# PCIE1_CORE_DBN_CFG_PCIE_CORE register map
Vendor: Texas Instruments
Registers are 32-bit, read-write, reset 0x0 unless marked. A register's access mark holds for its fields unless they carry their own. Offsets are as the file gives them; [hi:lo] are bit positions.

## PCIE1_CORE_DBN_CFG_PCIE_CORE (part 2 of 7)
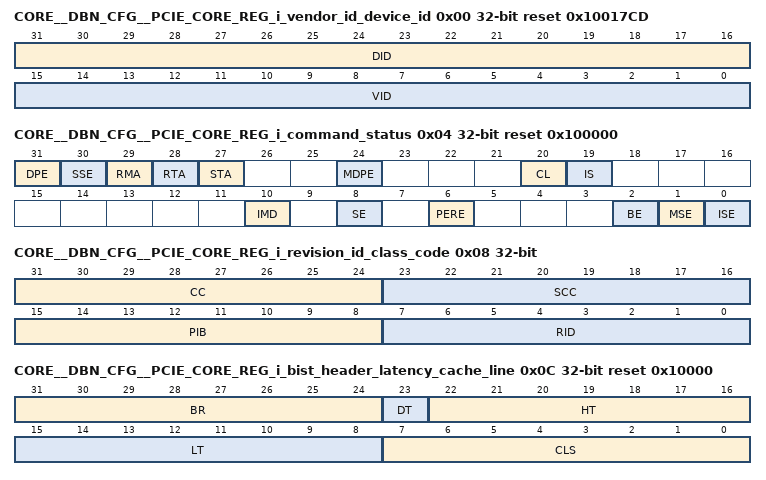
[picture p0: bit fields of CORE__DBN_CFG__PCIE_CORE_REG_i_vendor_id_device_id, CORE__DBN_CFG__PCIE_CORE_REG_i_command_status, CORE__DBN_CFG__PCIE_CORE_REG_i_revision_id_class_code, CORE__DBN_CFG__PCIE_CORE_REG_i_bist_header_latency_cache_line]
0x00 CORE__DBN_CFG__PCIE_CORE_REG_i_vendor_id_device_id ro reset 0x10017CD — 16-bit Vendor ID register and 16-bit Device ID register.
  [31:16] DID — Device ID assigned by the manufacturer of the device. On power-up, the Controller sets it to the value defined in the RTL file reg_defaults.h. This field can be written from the APB bus by setting [21] bit high of the pcie_mgmt_APB_ADDR during a local management register write.
  [15:0] VID — This is the Vendor ID assigned by PCI SIG to the manufacturer of the device. The Vendor ID is set in the Vendor ID Register within the local management register block.
0x04 CORE__DBN_CFG__PCIE_CORE_REG_i_command_status access not given reset 0x100000 — 16-bit Command Register and 16-bit Status Register.
  [31] DPE — This bit is set when the Controller has received a poisoned TLP. The Parity Error Response enable bit [bit 6] has no effect on the setting of this bit. This field can also be cleared from the local management bus APB by writing a 1 into this bit position. This field can be forced to 1 from the APB bus by setting [21] bit high of the pcie_mgmt_APB_ADDR during a local management register write. (access R/W1TC)
  [30] SSE — The Controller sets this bit [i]On receiving an error message from the link, if SERR-Enable in PCI Command Register is 1 and SERR-Enable in the Bridge Control Register is also 1. [ii]On any internal Fatal/Non-Fatal error detected, if SERR-Enable in PCI Command Register is 1. This field can also be cleared from the local management APB bus by writing a 1 into this bit position. This field can be forced to 1 from the APB bus by setting [21] bit high of the pcie_mgmt_APB_ADDR during a local management register write. (access R/W1TC)
  [29] RMA — This bit is set when the Controller has received a completion from the link with the Unsupported Request status. This field can also be cleared from the local management APB bus by writing a 1 into this bit position This field can be forced to 1 from the APB bus by setting [21] bit high of the pcie_mgmt_APB_ADDR during a local management register write. (access R/W1TC)
  [28] RTA — This bit is set when the Controller has received a completion from the link with the Completer Abort status. This field can also be cleared from the local management APB bus by writing a 1 into this bit position. This field can be written from the APB bus by setting [21] bit high of the pcie_mgmt_APB_ADDR during a local management register write. (access R/W1TC)
  [27] STA — This bit is set when the Controller has sent a completion to the link with the Completer Abort status. This field can also be cleared from the local management APB bus by writing a 1 into this bit position. This field can be forced to 1 from the APB bus by setting [21] bit high of the pcie_mgmt_APB_ADDR during a local management register write. (access R/W1TC)
  [24] MDPE — When the Parity Error Response enable bit is 1, the Controller sets this bit when it detects the following error conditions: [i] The Controller receives a poisoned request from the link. [ii] The Controller has sent a Poisoned Completion downstream to the link This bit remains 0 when the Parity Error Response enable bit is 0. This field can be forced to 1 from the APB bus by setting [21] bit high of the pcie_mgmt_APB_ADDR during a local management register write. (access R/W1TC)
  [20] CL ro — Indicates the presence of PCI Extended Capabilities registers. This bit is hardwired to 1.
  [19] IS ro — This bit is valid only when the Controller is configured to support legacy interrupts. Indicates that the Controller has a pending interrupt, that is, the Controller has sent an Assert_INTx message but has not transmitted a corresponding Deassert_INTx message.
  [10] IMD rw — Enables or disables the transmission of INTx Assert and De-assert messages from the Controller. The setting of this bit has no effect on the operation of the Controller in the RC mode.
  [8] SE rw — Enables the reporting of fatal and non-fatal errors detected by the Controller to the Root Complex.
  [6] PERE rw — When this bit is 1, the Controller sets the Master Data Parity Error status bit when it detects the following error conditions: [i] The Controller receives a poisoned completion from the link in response to a request. [ii] The Controller sends out a poisoned write request on the link [this may be because an underflow occurred during the packet transfer at the host interface of the Controller.]. When this bit is 0, the Master Data Parity Error status bit is never set.
  [2] BE rw — For a Function with a Type 1 Configurations Space header[Controller in RP Mode], this bit controls forwarding of Memory or I/O Requests by a Port in the Upstream direction. Note: The Controller does not generate any response based on this bit. Client application logic must use this bit and respond to requests appropriately: - When this bit is '1', Client logic can process the Memory and IO Requests received from PCIe Link normally. - When this bit is '0', Client logic must handle Memory and IO Requests received from PCIe Link as Unsupported Requests.
  [1] MSE rw — For a Function with a Type 1 Configuration Space header[Controller in RP Mode], this bit controls the response to Memory Space accesses received on its Primary Side. Note: The Controller does not generate any response based on this bit. - Client must check for this bit to be '1' before initiating any Memory requests on the pcie_master_AXI interface.
  [0] ISE rw — For a Function with a Type 1 Configuration Space header [Controller in RP Mode] , this bit controls the response to I/O Space accesses received on its Primary Side. Note: The Controller does not generate any response based on this bit. - Client must check for this bit to be '1' before initiating any IO requests on the pcie_master_AXI interface.
0x08 CORE__DBN_CFG__PCIE_CORE_REG_i_revision_id_class_code ro — This register contains the Revision ID and Class Code associated with the device incorporating the Cadence PCIe Controller.
  [31:24] CC — Identifies the function of the device. On power-up, the Controller sets it to the value defined in the RTL file reg_defaults.h. This field can be written from the APB bus by setting [21] bit high of the pcie_mgmt_APB_ADDR during a local management register write.
  [23:16] SCC — Identifies a sub-category within the selected function. This field can be written from the APB bus by setting [21] bit high of the pcie_mgmt_APB_ADDR during a local management register write.
  [15:8] PIB — Identifies the register set layout of the device. This field can be written from the APB bus by setting [21] bit high of the pcie_mgmt_APB_ADDR during a local management register write.
  [7:0] RID — Assigned by the manufacturer of the device to identify the revision number of the device. This field can be written from the APB bus by setting [21] bit high of the pcie_mgmt_APB_ADDR during a local management register write.
0x0C CORE__DBN_CFG__PCIE_CORE_REG_i_bist_header_latency_cache_line access per field reset 0x10000 — This location contains the BIST, header-type, Latency Timer and Cache Line Size Registers.
  [31:24] BR ro — BIST control register. This field can be written from the APB bus by setting [21] bit high of the pcie_mgmt_APB_ADDR during a local management register write.
  [23] DT ro — Identifies whether the device supports a single Function or multiple Functions. Hardwired to zero
  [22:16] HT ro — Identifies format of header. This field is hardwired to 1.
  [15:8] LT ro — This is an unused field and is hardwired to 0.
  [7:0] CLS rw — Cache Line Size Register defined in PCI Specifications 3.0. This field can be read or written, both from the link and from the local management bus, but its value is not used.
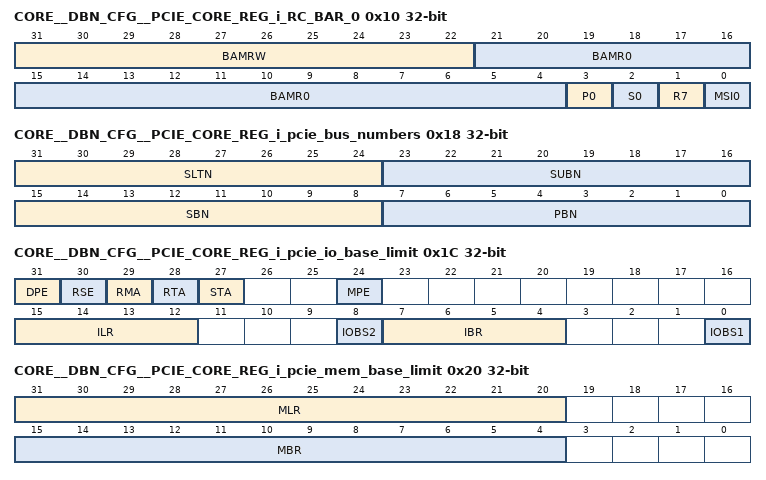
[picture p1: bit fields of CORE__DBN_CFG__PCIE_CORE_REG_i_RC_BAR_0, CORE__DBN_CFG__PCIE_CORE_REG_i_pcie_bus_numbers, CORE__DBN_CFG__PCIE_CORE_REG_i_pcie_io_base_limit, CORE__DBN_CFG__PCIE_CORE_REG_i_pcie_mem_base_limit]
0x10 CORE__DBN_CFG__PCIE_CORE_REG_i_RC_BAR_0 access per field — This is the Base Address Register 0 in the Type-1 Config Space. It can be configured as a 32-bit memory BAR, a 32-bit IO BAR, or can be paired with RC BAR 1 to form a 64-bit memory BAR. The parameters of this BAR are configured in the local management register Root Complex BAR Configuration Register.
  [31:22] BAMRW rw — This field defines the base address of the memory address range. The number of implemented bits in this field determines the BAR aperture configured in Root Complex BAR Configuration Register. All other bits are not writeable, and are read as 0's.
  [21:4] BAMR0 ro — This field defines the base address of the memory address range. The number of implemented bits in this field determines the BAR aperture configured in Root Complex BAR Configuration Register. All other bits are not writeable, and are read as 0's.
  [3] P0 ro — For memory BAR: This bit reads as 1 when BAR 0 is configured as a prefetchable BAR, and as 0 when configured as a non-prefetchable BAR. For IO BAR: This is bit 3 of the base address. The value read in this field is determined by the setting of Root Complex BAR Configuration Register.
  [2] S0 ro — For memory BAR:This bit reads as 0 when BAR 0 is configured as a 32-bit BAR, and as 1 when configured as a 64-bit BAR. For IO BAR: This is bit 3 of the base address. The value read in this field is determined by the setting of Root Complex BAR Configuration Register.
  [1] R7 ro — This bit is hardwired to 0 for both memory and I/O BARs.
  [0] MSI0 ro — Specifies whether this BAR defines a memory address range or an I/O address range [0 = memory, 1 = I/O]. The value read in this field is determined by the setting of Root Complex BAR Configuration Register.
0x14 CORE__DBN_CFG__PCIE_CORE_REG_i_RC_BAR_1 ro — This is the Base Address Register 1 in the Type-1 Config Space. It can be configured as a 32-bit memory BAR, a 32-bit IO BAR, or can be paired with RC BAR 0 to form a 64-bit memory BAR. The parameters of this BAR are configured in the local management register Root Complex BAR Configuration Register.
  [31:0] R7 — This field is reserved at power-on. This can be changed using BAR configuration regsiter in LM space.
0x18 CORE__DBN_CFG__PCIE_CORE_REG_i_pcie_bus_numbers access per field — This location contains the 8-bit fields: Primary Bus Number, Secondary Bus Number,Subordinate Bus Number, Secondary Latency Timer.
  [31:24] SLTN ro — This field is not implemented.
  [23:16] SUBN rw — This field can be read and written from the local management bus, but its value is not used within the Controller.
  [15:8] SBN rw — This field can be read and written from the local management bus, but its value is not used within the Controller.
  [7:0] PBN rw — This field can be read and written from the local management bus, but its value is not used within the Controller.
0x1C CORE__DBN_CFG__PCIE_CORE_REG_i_pcie_io_base_limit access not given — This location contains the 8-bit IO Base Register, the 8-bit IO Limit Register and the 16-bit Secondary Status Registers.
  [31] DPE — The Controller does not set this bit by itself. This bit can be cleared by writing a 1 into this bit position from the local management APB bus. This field can be forced to 1 or 0 from the APB bus by setting [21] bit high of the pcie_mgmt_APB_ADDR during a local management register write. (access R/W1TC)
  [30] RSE — The Controller does not set this bit by itself. This bit can be cleared by writing a 1 into this bit position from the local management APB bus. This field can be forced to 1 or 0 from the APB bus by setting [21] bit high of the pcie_mgmt_APB_ADDR during a local management register write. (access R/W1TC)
  [29] RMA — The Controller does not set this bit by itself. This bit can be cleared by writing a 1 into this bit position from the local management APB bus. This field can be forced to 1 or 0 from the APB bus by setting [21] bit high of the pcie_mgmt_APB_ADDR during a local management register write. (access R/W1TC)
  [28] RTA — The Controller does not set this bit by itself. This bit can be cleared by writing a 1 into this bit position from the local management APB bus. This field can be forced to 1 or 0 from the APB bus by setting [21] bit high of the pcie_mgmt_APB_ADDR during a local management register write. (access R/W1TC)
  [27] STA — The Controller does not set this bit by itself. This bit can be cleared by writing a 1 into this bit position from the local management APB bus. This field can be forced to 1 or 0 from the APB bus by setting [21] bit high of the pcie_mgmt_APB_ADDR during a local management register write. (access R/W1TC)
  [24] MPE — The Controller does not set this bit by itself. This bit can be cleared by writing a 1 into this bit position from the local management APB bus. This field can be forced to 1 or 0 from the APB bus by setting [21] bit high of the pcie_mgmt_APB_ADDR during a local management register write. Note that this bit can be set only when the Parity Error Response Enable bit is set in the Bridge Control Register (access R/W1TC)
  [15:12] ILR ro — This field can be read and written from the local management bus if IO BAR is enabled in the Root Complex BAR configuration register, else it is hardwired to zero. Its value is not used within the Controller.
  [8] IOBS2 ro — value set in Type1 cfg IO bar size[bit 20 of RC BAR CONFIG register].If type1 cfg IObar enable bit[bit 19 in RC BAR CONFIG register] is not set, then this field will be hard coded to 0.
  [7:4] IBR ro — This field can be read and written from the local management bus if IO BAR is enabled in the Root Complex BAR configuration register, else it is hardwired to zero. Its value is not used within the Controller.
  [0] IOBS1 ro — value set in Type1 cfg IO bar size[bit 20 of RC BAR CONFIG register]. If type1 cfg IObar enable bit[bit 19 in RC BAR CONFIG register] is not set, then this field will be hard coded to 0.
0x20 CORE__DBN_CFG__PCIE_CORE_REG_i_pcie_mem_base_limit — This location contains the 16-bit Memory Base Register and the 16-bit Memory Limit Register
  [31:20] MLR — This field can be read and written from the local management APB bus, but its value is not used within the Controller.
  [15:4] MBR — This field can be read and written from the local management APB bus, but its value is not used within the Controller.
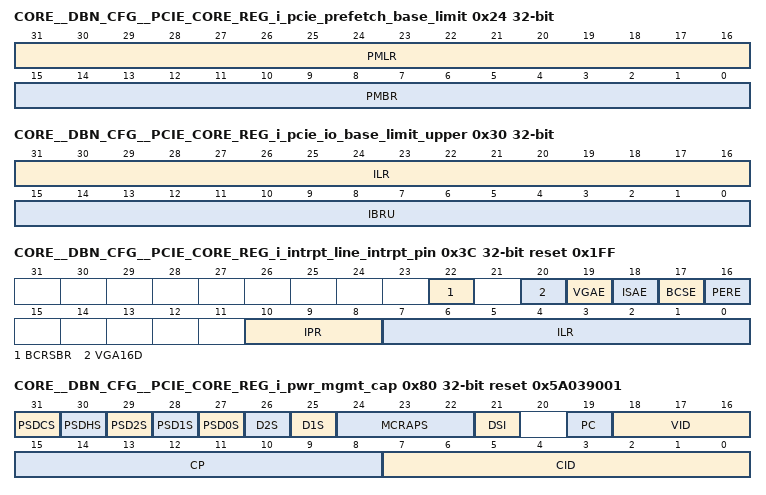
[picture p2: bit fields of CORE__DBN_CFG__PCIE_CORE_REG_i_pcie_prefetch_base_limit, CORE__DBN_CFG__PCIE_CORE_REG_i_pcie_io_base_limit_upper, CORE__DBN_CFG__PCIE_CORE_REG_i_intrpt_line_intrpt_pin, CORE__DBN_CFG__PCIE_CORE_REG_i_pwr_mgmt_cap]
0x24 CORE__DBN_CFG__PCIE_CORE_REG_i_pcie_prefetch_base_limit ro — This location contains the Prefetchable Memory Base Register and the Prefetchable Memory Limit Register. This register is enabled by programming the Root Complex BAR configuration register in the Local Management space
  [31:16] PMLR — This field can be read and written from the local management APB bus if prefetchable memory is enabled in the Root Complex BAR configuration register, else it is hardwired to zero. Its value is not used within the Controller.
  [15:0] PMBR — This field can be read and written from the local management APB bus if prefetchable memory is enabled in the Root Complex BAR configuration register, else it is hardwired to zero. Its value is not used within the Controller.
0x28 CORE__DBN_CFG__PCIE_CORE_REG_i_pcie_prefetch_base_upper ro — This location contains the upper 32 bits of the Prefetchable Base Register. This register is enabled by programming the Root Complex BAR configuration register in the Local Management space.
  [31:0] PBRU — This field can be read and written from the local management APB bus if 64bit prefetchable memory is enabled in the Root Complex BAR configuration register, else it is hardwired to zero. Its value is not used within the Controller.
0x2C CORE__DBN_CFG__PCIE_CORE_REG_i_pcie_prefetch_limit_upper ro — This location contains the upper 32 bits of the Prefetchable Limit Register. This register is enabled by programming the Root Complex BAR configuration register in the Local Management space.
  [31:0] PLRU — This field can be read and written from the local management APB bus if 64bit prefetchable memory is enabled in the Root Complex BAR configuration register, else it is hardwired to zero. Its value is not used within the Controller.
0x30 CORE__DBN_CFG__PCIE_CORE_REG_i_pcie_io_base_limit_upper ro — This location contains the upper 16 bits of the IO Base and IO Limit Registers
  [31:16] ILR — This field can be read and written from the local management bus if 32bit IO BAR is enabled in the Root Complex BAR configuration register, else it is hardwired to zero. Its value is not used within the Controller.
  [15:0] IBRU — This field can be read and written from the local management bus if 32bit IO BAR is enabled in the Root Complex BAR configuration register, else it is hardwired to zero. Its value is not used within the Controller.
0x34 CORE__DBN_CFG__PCIE_CORE_REG_i_capabilities_pointer ro reset 0x80 — This location contains the pointer to the first PCI Capabilities Structure.
  [7:0] CP — Contains pointer to the first PCI Capability Structure. This field is set by default to the value defined in the RTL file reg_defaults.h. It can be re-written independently for every Function from the local management APB bus.
0x38 CORE__DBN_CFG__PCIE_CORE_REG_rsvd_0E access not given reset not defined — Reserved
0x3C CORE__DBN_CFG__PCIE_CORE_REG_i_intrpt_line_intrpt_pin access per field reset 0x1FF — This location contains the Interrupt Line Register, the Interrupt Pin Register, and the Bridge Control Register
  [22] BCRSBR rw — This field can be read and written from the local management APB bus. When set, it initiates a hot reset on the link.
  [20] VGA16D rw — This field can be read and written from the local management APB bus, but its value is not used within the Controller.
  [19] VGAE rw — This field can be read and written from the local management APB bus, but its value is not used within the Controller.
  [18] ISAE rw — This field can be read and written from the local management APB bus, but its value is not used within the Controller.
  [17] BCSE rw — This field can be read and written from the local management APB bus, but its value is not used within the Controller.
  [16] PERE rw — This field can be read and written from the local management APB bus. It is used only to enable the Master Data Parity Error bit in the Secondary Status Register.
  [10:8] IPR ro — Identifies the interrupt input [A, B, C, D] to which this Functions interrupt output is connected to [01 = INTA, 02 = INTB, 03 = INTC, 04 = INTD]. The assignment of interrupt inputs to Functions is fixed when the Controller is configured. This field can be re-written independently for each Function from the local management bus. Default values - PF0: 01 [INTA], PF1: 02 [INTB].
  [7:0] ILR rw — This field can be read and written from the local management bus, but its value is not used within the Controller.The given reset value is for PF0.
0x80 CORE__DBN_CFG__PCIE_CORE_REG_i_pwr_mgmt_cap ro reset 0x5A039001 — This location contains the Power Management Capabilities Register, its Capability ID, and a pointer to the next capability. In the RC mode, the settings of the fields of this register have no effect on the operation of the Controller
  [31] PSDCS — Indicates whether the Function is capable of sending PME messages when in the D3cold state. This field can be written from the APB bus by setting [21] bit high of the pcie_mgmt_APB_ADDR during a local management register write.
  [30] PSDHS — Indicates whether the Function is capable of sending PME messages when in the D3hot state. This field can be written from the APB bus by setting [21] bit high of the pcie_mgmt_APB_ADDR during a local management register write.
  [29] PSD2S — Indicates whether the Function is capable of sending PME messages when in the D2 state. This bit is hardwired to 0 because D2 state is not supported.
  [28] PSD1S — Indicates whether the Function is capable of sending PME messages when in the D1 state. This bit is set to 1 by default, but can be modified from the local management bus by writing into Function 0. All other Functions assume the value set in Function 0s Power Management Capabilities Register.
  [27] PSD0S — Indicates whether the Function is capable of sending PME messages when in the D0 state. This field can be written from the APB bus by setting [21] bit high of the pcie_mgmt_APB_ADDR during a local management register write.
  [26] D2S — Set if the Function supports the D2 power state. Currently hardwired to 0.
  [25] D1S — Set if the Function supports the D1 power state. This field can be written from the APB bus by setting [21] bit high of the pcie_mgmt_APB_ADDR during a local management register write.
  [24:22] MCRAPS — Specifies the maximum current drawn by the device from the aux power source in the D3cold state. This field is not implemented in devices not supporting PME notification when in the D3cold state, and is therefore hardwired to 0.
  [21] DSI — This bit, when set, indicates that the device requires additional configuration steps beyond setting up its PCI configuration space, to bring it to the D0 active state from the D0 uninitialized state. This bit is hardwired to 0.
  [19] PC — Not applicable to PCI Express. This bit is hardwired to 0.
  [18:16] VID — Indicates the version of the PCI Bus Power Management Specifications that the Function implements. This field is set by default to 011 [Version 1.2]. This field can be written from the APB bus by setting [21] bit high of the pcie_mgmt_APB_ADDR during a local management register write.
  [15:8] CP — Contains pointer to the next PCI Capability Structure. The Controller sets it to the value defined in the RTL file reg_defaults.h. This field can be written from the APB bus by setting [21] bit high of the pcie_mgmt_APB_ADDR during a local management register write.
  [7:0] CID — Identifies that the capability structure is for Power Management. This field is set by default to 01 hex. This field can be written from the APB bus by setting [21] bit high of the pcie_mgmt_APB_ADDR during a local management register write.
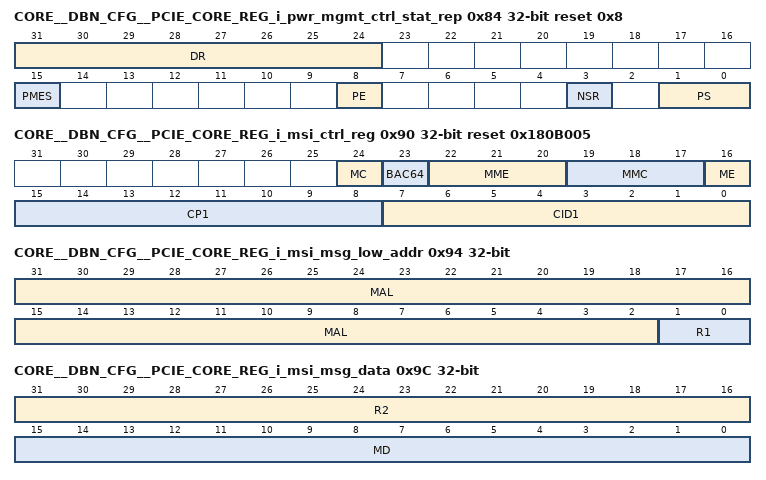
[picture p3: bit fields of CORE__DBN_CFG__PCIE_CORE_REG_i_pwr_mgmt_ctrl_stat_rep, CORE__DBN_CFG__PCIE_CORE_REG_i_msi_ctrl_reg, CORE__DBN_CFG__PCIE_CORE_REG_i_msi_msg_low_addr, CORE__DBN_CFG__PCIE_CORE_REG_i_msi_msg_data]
0x84 CORE__DBN_CFG__PCIE_CORE_REG_i_pwr_mgmt_ctrl_stat_rep access not given reset 0x8 — This location contains the Power Management Control/Status and Data Registers.
  [31:24] DR ro — This optional register is not implemented in the Cadence PCIe Controller. This field is hardwired to 0.
  [15] PMES — This field can be written from the APB bus by setting [21] bit high of the pcie_mgmt_APB_ADDR during a local management register write.. (access R/W1TC)
  [8] PE rw — This bit can be set or cleared from the local management APB bus, by writing a 1 or 0, respectively.
  [3] NSR ro — This bit is set to 1 by default. This field can be written from the APB bus by setting [21] bit high of the pcie_mgmt_APB_ADDR during a local management register write.
  [1:0] PS rw — This field can also be read or written from the local management APBbus.
0x90 CORE__DBN_CFG__PCIE_CORE_REG_i_msi_ctrl_reg access per field reset 0x180B005 — This register is used only when the Controller is configured to support Message Signaled Interrupts (MSIs). In addition to the MSI control bits, this location also contains the Capability ID for MSI and the pointer to the next PCI Capability Structure.
  [24] MC ro — can be modified using localmanagement interface
  [23] BAC64 ro — Set to 1 to indicate that the device is capable of generating 64-bit addresses for MSI messages.Can be modified using local management interface
  [22:20] MME rw — Encodes the number of distinct messages that the Controller is programmed to generate for this Function [000 = 1, 001 = 2, 010 = 4, 011 = 8, 100 = 16, 101 = 32]. This setting must be based on the number of interrupt inputs of the Controller that are actually used by this Function. This field can be written from the local management bus.
  [19:17] MMC ro — Encodes the number of distinct messages that the Controller is capable of generating for this Function [000 = 1, 001 = 2, 010 = 4, 011 = 8, 100 = 16, 101 = 32]. Thus, this field defines the number of the interrupt vectors for this Function. The Controller allows up to 32 distinct messages, but the setting of this field must be based on the number of interrupt inputs of the Controller that are actually used by the client. For example, if the client logic uses 8 of the 32 distinct MSI interrupt inputs of the Controller for this Function, then the value of this field must be set to 011. This field can be written from the local management bus. Please see the define den_db_Fx_MSI_MULTIPLE_MSG_CAPABLE values [where x is the function number] for default values of each function in the reg_defaults.v files.
  [16] ME rw — Set by the configuration program to enable the MSI feature. This field can also be written from the local management bus.
  [15:8] CP1 ro — Pointer to the next PCI Capability Structure. This can be modified from the local management bus. This field can be written from the local management bus.
  [7:0] CID1 ro — Specifies that the capability structure is for MSI. Hardwired to 05 hex.
0x94 CORE__DBN_CFG__PCIE_CORE_REG_i_msi_msg_low_addr access per field — This register contains the first 32 bits of the address to be used in the MSI messages generated by the Controller for this Function. This address is taken as a 32-bit address if the value programmed in the MSI Message High Address Register is 0. Otherwise, this address is taken as the least significant 32 bits of the 64-bit address sent in MSI messages.
  [31:2] MAL rw — Lower bits of the address to be used in MSI messages. This field can also be written from the local management bus.
  [1:0] R1 ro — The two lower bits of the address are hardwired to 0 to align the address on a double-word boundary.
0x98 CORE__DBN_CFG__PCIE_CORE_REG_i_msi_msg_hi_addr — This register contains the most significant 32 bits of the 64-bit address sent by the Controller in MSI messages. A value of all zeroes in this register is taken to mean that the Controller should use 32-bit addresses in the messages.
  [31:0] MAH — Contains bits 63:32 of the 64-bit address to be used in MSI Messages. A value of 0 specifies that 32-bit addresses are to be used in the messages. This field can also be written from the local management bus.
0x9C CORE__DBN_CFG__PCIE_CORE_REG_i_msi_msg_data access per field — This register contains the write data to be used in the MSI messages to be generated for the associated PCI Function. When the number of distinct messages programmed in the MSI Control Register is 1, the 32-bit value from this register is used as the data value in the MSI packets generated by the Controller for this Function. If the number of distinct messages is more than 1, the least significant bits of the programmed value are replaced with the encoded interrupt vector [31:0] of the specific message to generate the write data value for the message.
  [31:16] R2 ro — Hardwired to 0
  [15:0] MD rw — Message data to be used for this Function. This field can also be written from the local management bus.
0xA0 CORE__DBN_CFG__PCIE_CORE_REG_i_msi_mask — This register contains the MSI mask bits, one for each of the interrupt levels.
  [0] MM — Mask bits for MSI interrupts. The Multiple Message Capable field of the MSI Control Register specifies the number of distinct interrupts for the Function, which determines the number of valid mask bits.
0xA4 CORE__DBN_CFG__PCIE_CORE_REG_i_msi_pending_bits ro — This register contains the MSI pending interrupt bits, one for each of the interrupt levels.
  [0] MP — Pending bits for MSI interrupts. This field can be written from the APB interface to refelct the current pending status.
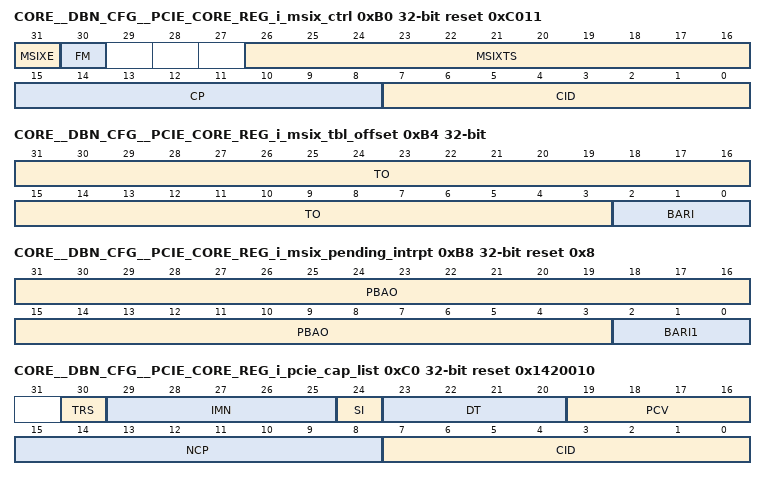
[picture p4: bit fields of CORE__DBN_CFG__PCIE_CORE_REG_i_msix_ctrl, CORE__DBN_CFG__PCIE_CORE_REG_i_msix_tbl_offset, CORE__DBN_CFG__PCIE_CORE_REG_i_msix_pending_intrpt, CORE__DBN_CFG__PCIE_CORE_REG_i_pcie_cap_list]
0xB0 CORE__DBN_CFG__PCIE_CORE_REG_i_msix_ctrl access per field reset 0xC011 — This register contains the MSI-X configuration bits, the Capability ID for MSI-X and the pointer to the next PCI Capability Structure.
  [31] MSIXE rw — Set by the configuration program to enable the MSI-X feature. This field can also be written from the local management bus.
  [30] FM rw — This bit serves as a global mask to all the interrupt conditions associated with this Function. When this bit is set, the Controller will not send out MSI-X messages from this Function. This field can also be written from the local management bus.
  [26:16] MSIXTS ro — Specifies the size of the MSI-X Table, that is, the number of interrupt vectors defined for the Function. The programmed value is 1 minus the size of the table [that is, this field is set to 0 if the table size is 1.]. It can be re-written independently for each Function from the local management bus. Please see the define den_db_Fx_MSIX_TABLE_SIZE values [where x is the function number] for default values of each function in the reg_defaults.v files.
  [15:8] CP ro — Contains pointer to the next PCI Capability Structure. This is set to point to the PCI Express Capability Structure at 30 hex. This can be rewritten independently for each Function from the local management bus.
  [7:0] CID ro — Identifies that the capability structure is for MSI-X. This field is set by default to 11 hex. It can be rewritten independently for each Function from the local management bus.
0xB4 CORE__DBN_CFG__PCIE_CORE_REG_i_msix_tbl_offset ro — This register is used to specify the location of the MSI-X Table in memory. All the 32 bits of this register can be re-written independently for each Function from the local management bus.
  [31:3] TO — Offset of the memory address where the MSI-X Table is located, relative to the selected BAR. The three least significant bits of the address are omitted, as the addresses are QWORD aligned. Please see the define den_db_Fx_MSIX_TABLE_OFFSET values [where x is the function number] for default values of each function in the reg_defaults.v files.
  [2:0] BARI — Identifies the BAR corresponding to the memory address range where the MSI-X Table is located [000 = BAR 0, 001 = BAR 1, ... , 101 = BAR 5]. Please see the define den_db_Fx_MSIX_TABLE_BIR values [where x is the function number] for default values of each function in the reg_defaults.v files.
0xB8 CORE__DBN_CFG__PCIE_CORE_REG_i_msix_pending_intrpt ro reset 0x8 — This register is used to specify the location of the MSI-X Pending Bit Array (PBA). The PBA is a structure in memory containing the pending interrupt bits. All the 32 bits of this register can be rewritten independently for each Function from the local management bus.
  [31:3] PBAO — Offset of the memory address where the PBA is located, relative to the selected BAR. The three least significant bits of the address are omitted, as the addresses are QWORD aligned. Please see the define den_db_Fx_MSIX_PBA_OFFSET values [where x is the function number] for default values of each function in the reg_defaults.v files.
  [2:0] BARI1 — Identifies the BAR corresponding to the memory address range where the PBA Structure is located [000 = BAR 0, 001 = BAR 1, ... , 101 = BAR 5]. The value programmed must be the same as the BAR Indicator configured in the MSI-X Table Offset Register.Identifies the BAR corresponding to the memory address range where the PBA Structure is located [000 = BAR 0, 001 = BAR 1, ... , 101 = BAR 5]. The value programmed must be the same as the BAR Indicator configured in the MSI-X Table Offset Register. Please see the define den_db_Fx_MSIX_PBA_BIR values [where x is the function number] for default values of each function in the reg_defaults.v files.
0xC0 CORE__DBN_CFG__PCIE_CORE_REG_i_pcie_cap_list ro reset 0x1420010 — This location identifies the PCI Express device type and its capabilities. It also contains the Capability ID for the PCI Express Structure and the pointer to the next capability structure.
  [30] TRS — When set to 1, this bit indicates that the device supports routing of Trusted Configuration Requests. Not valid for Endpoints. Hardwired to 0.
  [29:25] IMN — Identifies the MSI or MSI-X interrupt vector for the interrupt message generated corresponding to the status bits in the Slot Status Register, Root Status Register, or this capability structure. This field must be defined based on the chosen interrupt mode - MSI or MSI-X. This field is hardwired to 0.
  [24] SI — When Set, this bit indicates that the Link associated with this Port is connected to a slot
  [23:20] DT — Indicates the type of device implementing this Function. This field is hardwired to 4 in the RP mode.
  [19:16] PCV — Identifies the version number of the capability structure. This field is set to 2 by default to indicate that the Controller is compatible to PCI Express Base Specification Revision 3.0. Can be modified using local management interface after asserting input signal MGMT_TYPE1_CONFIG_REG_ACCESS high.
  [15:8] NCP — Points to the next PCI capability structure. Set to 0 because this is the last capability structure.
  [7:0] CID — Specifies Capability ID assigned by PCI SIG for this structure. This field is hardwired to 10 hex.
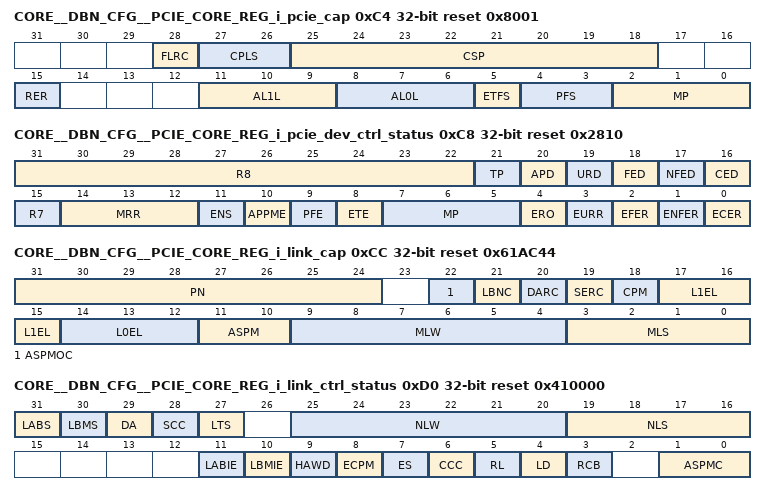
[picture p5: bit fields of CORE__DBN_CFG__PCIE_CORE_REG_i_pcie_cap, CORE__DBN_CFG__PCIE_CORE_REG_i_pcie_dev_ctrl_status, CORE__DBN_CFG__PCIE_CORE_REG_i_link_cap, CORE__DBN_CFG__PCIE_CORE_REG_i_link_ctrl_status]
0xC4 CORE__DBN_CFG__PCIE_CORE_REG_i_pcie_cap ro reset 0x8001 — This register advertises the capabilities of the PCI Express device.
  [28] FLRC — A value of 1b indicates the Function supports the optional Function Level Reset mechanism
  [27:26] CPLS — Specifies the scale used by Slot Power Limit Value. This field can be written from the APB bus by setting [21] bit high of the pcie_mgmt_APB_ADDR during a local management register write. .
  [25:18] CSP — Specifies upper limit on power supplied by slot. This field can be written from the APB bus by setting [21] bit high of the pcie_mgmt_APB_ADDR during a local management register write. .
  [15] RER — Enables role-based errer reporting. This field can be written from the APB bus by setting [21] bit high of the pcie_mgmt_APB_ADDR during a local management register write.
  [11:9] AL1L — Specifies acceptable latency that the Endpoint can tolerate while transitioning from L1 to L0. This field can be written from the APB bus by setting [21] bit high of the pcie_mgmt_APB_ADDR during a local management register write.
  [8:6] AL0L — Specifies acceptable latency that the Endpoint can tolerate while transitioning from L0S to L0. This field can be written from the APB bus by setting [21] bit high of the pcie_mgmt_APB_ADDR during a local management register write.
  [5] ETFS — hard coded to zero .
  [4:3] PFS — This field is used to extend the tag field by combining unused Function bits with the tag bits. This field is hardwired to 00 to disable this feature.
  [2:0] MP — Specifies maximum payload size supported by the device. This field can be written from the APB bus by setting [21] bit high of the pcie_mgmt_APB_ADDR during a local management register write.
0xC8 CORE__DBN_CFG__PCIE_CORE_REG_i_pcie_dev_ctrl_status access not given reset 0x2810 — This register contains control and status bits associated with the device.
  [31:22] R8 ro
  [21] TP ro — Indicates if any of the Non-Posted requests issued by the RC are still pending.
  [20] APD ro — Set when auxiliary power is detected by the device. This is an unused field.
  [19] URD — Set to 1 by the Controller when it receives an unsupported request. (access R/W1TC)
  [18] FED — Set to 1 by the Controller when it detects a fatal error, regardless of whether the error is masked. (access R/W1TC)
  [17] NFED — Set to 1 by the Controller when it detects a non-fatal error, regardless of whether the error is masked. (access R/W1TC)
  [16] CED — Set to 1 by the Controller when it detects a correctable error, regardless of whether the error is masked. (access R/W1TC)
  [15] R7 ro — Hardwired to 0.
  [14:12] MRR rw — Specifies the maximum size allowed in read requests generated by the device.
  [11] ENS rw — If this bit is Set, the Function is permitted to Set the No Snoop bit in the Requester Attributes of transactions it initiates that do not require hardware enforced cache coherency.
  [10] APPME ro — Hardwired to 0
  [9] PFE ro — Hardwired to 0
  [8] ETE ro — extended tag not enabled. Hence hard coded to zero .
  [7:5] MP rw — Specifies the maximum TLP payload size configured. The device must be able to receive a TLP of this maximum size, and should not generate TLP's larger than this value. Software must set this field based on the maximum payload size in the Device Capabilities Register, and the capability of the other side.
  [4] ERO rw — When set, this bit indicates that the device is allowed to set the Relaxed Ordering bit in the Attributes field of transactions initiated from it., when the transactions do not require Strong Ordering.
  [3] EURR rw — This bit is used to gate the CORRECTABLE_ERROR_OUT, NON_FATAL_ERROR_OUT, FATAL_ERROR_OUT output in Root Port mode on receiving unsupported requests. Note: Alternately, the SERR Enable bit in the Command Register can also be set to enable assertion of FATAL_ERROR_OUT on receiving uncorrectable unsupported requests.
  [2] EFER rw — This bit is used to gate the FATAL_ERROR_OUT output of the Controller in Root Port mode. When an Uncorrectable, Unmasked Error with Uncorrectable Error Severity set to 1 is detected Internally or when a ERR_FATAL message is received by the Controller, in Root Port mode, this bit gates the assertion of FATAL_ERROR_OUT output. Note: Alternately, the SERR Enable bit in the Command Register can also be set to enable assertion of FATAL_ERROR_OUT.
  [1] ENFER rw — This bit is used to gate the NON_FATAL_ERROR_OUT output of the Controller in Root Port mode. When an Uncorrectable, Unmasked Error with Uncorrectable Error Severity set to 0 is detected Internally or when a ERR_NON_FATAL message is received by the Controller, in Root Port mode, this bit gates the assertion of NON_FATAL_ERROR_OUT output. Note: Alternately, the SERR Enable bit in the Command Register can also be set to enable assertion of NON_FATAL_ERROR_OUT.
  [0] ECER rw — This bit is used to gate the CORRECTABLE_ERROR_OUT output of the Controller in Root Port mode. When a Correctable and Unmasked Error is detected Internally or when a ERR_CORR message is received by the Controller, in Root Port mode, this bit gates the assertion of CORRECTABLE_ERROR_OUT output.
0xCC CORE__DBN_CFG__PCIE_CORE_REG_i_link_cap ro reset 0x61AC44 — This register advertises the link-specific capabilities of the device incorporating the Cadence PCIe Controller.
  [31:24] PN — Specifies the port number assigned to the PCI Express link connected to this device. This field can be written from the APB bus by setting [21] bit high of the pcie_mgmt_APB_ADDR during a local management register write.
  [22] ASPMOC — A 1 in this position indicates the device supports the ASPM Optionality feature. This field can be written from the APB bus by setting [21] bit high of the pcie_mgmt_APB_ADDR during a local management register write.
  [21] LBNC — A value of 1b indicates support for the Link Bandwidth Notification status and interrupt mechanisms. This field can be written from the APB bus by setting [21] bit high of the pcie_mgmt_APB_ADDR during a local management register write.
  [20] DARC — Set to 1 if the device is capable of reporting that the DL Control and Management State Machine has reached the DL_Active state. This bit is hardwired to 0, as this version of the Controller does not support the feature.
  [19] SERC — Indicates the capability of the device to report a Surprise Down error condition. This bit is hardwired to 0, as this version of the Controller does not support the feature.
  [18] CPM — Indicates that the device supports removal of reference clocks. Not supported in this version of the Controller. Hardwired to 0.
  [17:15] L1EL — Specifies the exit latency from L1 state. This parameter is dependent on the Physical Layer implementation. This field can be written from the APB bus by setting [21] bit high of the pcie_mgmt_APB_ADDR during a local management register write.
  [14:12] L0EL — Specifies the time required for the device to transition from L0S to L0. This parameter is dependent on the Physical Layer implementation. This field can be written from the APB bus by setting [21] bit high of the pcie_mgmt_APB_ADDR during a local management register write.
  [11:10] ASPM — Indicates the level of ASPM support provided by the device. This field can be written from the APB bus by setting [21] bit high of the pcie_mgmt_APB_ADDR during a local management register write.
  [9:4] MLW — Indicates the maximum number of lanes supported by the device. This field is hardwired based on the setting of the LANE_COUNT_IN strap input.
  [3:0] MLS — Indicates the speeds supported by the link [2.5 GT/s , 5 GT/s , 8 GT/s , 16 GT/s per lane]. This field is hardwired to 0001 [2.5GT/s] when the strap input PCIE_GENERATION_SEL is set to 0, to 0010 [5 GT/s] when the strap is set to 1 , and to 0011 [8 GT/s] when the strap input is set to 10 , and to 0100 [16 GT/s] when the strap input is set to 11 .
0xD0 CORE__DBN_CFG__PCIE_CORE_REG_i_link_ctrl_status access not given reset 0x410000 — This register contains control and status bits specific to the PCI Express link.
  [31] LABS — This bit is Set by hardware to indicate that hardware has autonomously changed Link speed or width, without the Port transitioning through DL_Down status, for reasons other than to attempt to correct unreliable Link operation. This triggers an interrupt to be generated through PHY_INTERRUPT_OUT if enabled. Hardwired to 0 if Link Bandwidth Notification Capability is 0. (access R/W1TC)
  [30] LBMS — This bit is Set by hardware to indicate that either link training has completed following write to retrain link bit, or when HW has changed link speed or width to attempt to correct unreliable link operation. This triggers an interrupt to be generated through PHY_INTERRUPT_OUT if enabled. Hardwired to 0 if Link Bandwidth Notification Capability is 0. (access R/W1TC)
  [29] DA ro — Indicates the status of the Data Link Layer. Set to 1 when the DL Control and Management State Machine has reached the DL_Active state. This bit is hardwired to 0 in this version of the Controller.
  [28] SCC ro — Indicates that the device uses the reference clock provided by the connector. This field can be written from the APB bus by setting [21] bit high of the pcie_mgmt_APB_ADDR during a local management register write.
  [27] LTS ro — This bit is set to 1 when the LTSSM is in the Recovery or Configuration states, or if a 1 has been written to the Retrain Link bit but the link training has not yet begun.
  [25:20] NLW ro — Set at the end of link training to the actual link width negotiated between the two sides.
  [19:16] NLS ro — Negotiated link speed of the device. The only supported speed ids are 2.5 GT/s per lane [0001],5 GT/s per lane [0010] ,8 GT/s per lane [0011],16 GT/s per lane [0100].
  [11] LABIE rw — When Set, this bit enables the generation of an interrupt to indicate that the Link Autonomous Bandwidth Status bit has been Set. This enables an interrupt to be generated through PHY_INTERRUPT_OUT if triggered. Hardwired to 0 if Link Bandwidth Notification Capability is 0.
  [10] LBMIE rw — When Set, this bit enables the generation of an interrupt to indicate that the Link Bandwidth Management Status bit has been Set. This enables an interrupt to be generated through PHY_INTERRUPT_OUT if triggered. Hardwired to 0 if Link Bandwidth Notification Capability is 0.
  [9] HAWD rw — When this bit is set, the local application must not request to change the operating width of the link, other than attempting to correct unreliable Link operation by reducing Link width.
  [8] ECPM ro — This field is hardwired to 0 when the Controller is in the RC mode.
  [7] ES rw — Set to 1 to extend the sequence of ordered sets transmitted while exiting from the L0S state.
  [6] CCC rw — A value of 0 indicates that the reference clock of this device is asynchronous to that of the upstream device. A value of 1 indicates that the reference clock is common.
  [5] RL ro — Setting this bit to 1 causes the LTSSM to initiate link training. This bit always reads as 0. This bit can be set by Host SW at any time independent of the LTSSM state. If the LTSSM is not in L0 state, the Controller will internally register the retrain command and initiate the link retrain immediately after the LTSSM reaches L0. For example, if the LTSSM is already in Recovery, the Controller will initiate Retrain Link after the LTSSM transitions back to L0 state.
  [4] LD rw — Writing a 1 to this bit position causes the LTSSM to go to the Disable Link state. The LTSSM stays in the Disable Link state while this bit is set.
  [3] RCB ro — Indicates the Read Completion Boundary of the Root Port [0 = 64 bytes, 1 = 128 bytes]. This field can be written from the APB bus by setting [21] bit high of the pcie_mgmt_APB_ADDR during a local management register write.
  [1:0] ASPMC rw — Controls the level of ASPM support on the PCI Express link associated with the function. The valid setting are 00: ASPM disabled 01: L0s entry enabled, L1 disabled 10: L1 entry enabled, L0s disabled 11: Both L0s and L1 enabled. Note that the ASPM Control bits can be enabled only if the corresponding ASPM Support[1:0] bit is 1 in the Link Capabilities Register.
